# netx90_app register map
File version: 1.0
CPU: CM4 r0p1, little endian, MPU, FPU, 4 interrupt priority bits, 78 interrupts
Registers are 32-bit, read-write, reset 0x0 unless marked. A register's access mark holds for its fields unless they carry their own. Offsets are from the block's base; [hi:lo] are bit positions; {n}, {i} and the like mark numbered series; 'fields as' and 'values as' point back to an identical list.

## idpm_com
Base 0xFF001B00
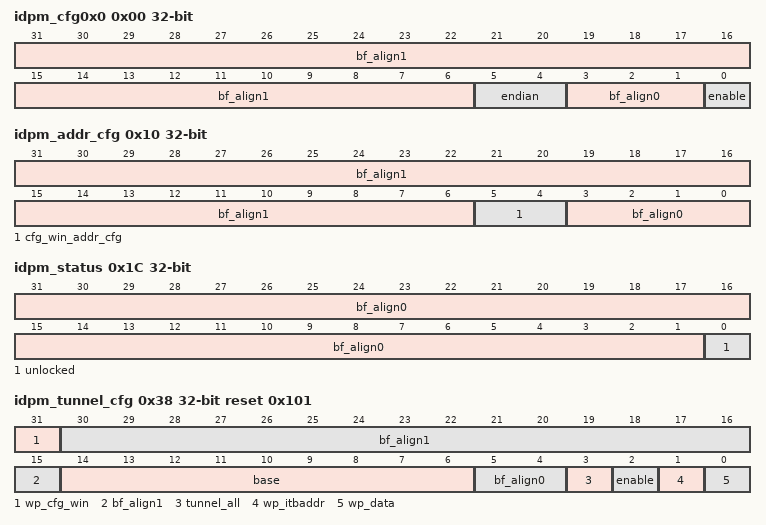
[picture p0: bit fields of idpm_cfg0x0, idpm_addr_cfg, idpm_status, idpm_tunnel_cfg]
0x00 idpm_cfg0x0 (reset mask 0x31) — DPM IO Control Register 0.
  [31:6] bf_align1 — bitField alignment value for aeabi compatibility
  [5:4] endian — Endianess of 32 bit (DWord) address alignment (B0: least significant byte, B3: most significant byte): { | | | | | coding Address A+3 A+2 A+1 A+0 00 little endian B3 B2 B1 B0 01 16 bit big endian B2 B3 B0 B1 10 32 bit big endian B0 B1 B2 B3 11 reserved } Little endian is used netX inside. If big endian host device is used, set to this 01 or 10 according to host device data width.
  [3:1] bf_align0 — bitField alignment value for aeabi compatibility
  [0] enable — Global IDPM enable bit. The IDPM module must be enabled by the INTLOGIC area before the host area (i.e. DPM mirrors of INTRAMHS) can be used. While disabled all host access (access to DPM mirrors of INTRAMHS) will be ignored. Read will return 0x0bad0bad.
0x10 idpm_addr_cfg (reset mask 0x30) — DPM External Address Configuration Register.
  [31:6] bf_align1 — bitField alignment value for aeabi compatibility
  [5:4] cfg_win_addr_cfg — Location of the DPM Configuration Window (Window 0). Supported settings are: 00: Low Configuration Window: The Configuration Window is located in the first 256 bytes of external DPM address range (0x0 to 0xff). It is located before the first enabled Data Window (1 to 4). 01: High Configuration Window: The Configuration Window is located in the last 256 bytes of external DPM address range. Example: 'addr_range' is 8kB: Configuration Window is located in 0x1F00..0x1FFF. 10: reserved. 11: Configuration Window is disabled for external DPM access. Full DPM address range can be used for Windows 1 to 4. Note: The Configuration Window 0 has higher priority than normal DPM Window. The location of the Configuration Window does not depend on the Data Window configuration (the setting of the 'dpm_winX_end' or 'dpm_winX_map' registers). I.e. for setting '00' (low Configuration Window) the first enabled Data Window starts at address 0x100. For setting '01' (high Configuration Window) it would hide the last 256 bytes of the last enabled Data Window when this is configured to end on the last external address. The Configuration Window 0 has lower priority than Access Tunnel. I.e. the Access Tunnel could be laid over the configuration window.
  [3:0] bf_align0 — bitField alignment value for aeabi compatibility
0x1C idpm_status ro (reset mask 0x1) — DPM Status Register.
  [31:1] bf_align0 — bitField alignment value for aeabi compatibility
  [0] unlocked — DPM is locked during netX power up and boot phase. DPM access to other addresses than DPM configuration window 0 cannot be done before this bit is set to 1. Write access to data windows (netX AHB area) will be ignored and read access will deliver invalid data while locked. Poll for 1 after power-up or reset.
0x38 idpm_tunnel_cfg reset 0x101 (reset mask 0x80007FCF) — description too long, please enter short description.
  [31] wp_cfg_win — Write-protect tunnel configuration inside the configuration window 0. 0: The two tunnel configuration registers ('idpm_tunnel_cfg' and 'idpm_itbaddr') can be programmed via configuration window 0 and the INTLOGIC_SYS-IDPM address area. 1: The tunnel configuration registers ('idpm_tunnel_cfg' and 'idpm_itbaddr') cannot be programmed by the host via configuration window 0 (they are read-only for the host there). They can only be programmed via the INTLOGIC_SYS-IDPM address area. Note: Set this bit to protect the NETX from reconfiguring the tunnel by the host when configuration window 0 is activated for the host (e.g. for IRQ handling).
  [30:15] bf_align1 — bitField alignment value for aeabi compatibility
  [14:6] base — DPM Access Tunnel (DATunnel) Base Address divided by 64 on external visible address space. Note: Default setting for tunnel base is starting on external address 0x100.
  [5:4] bf_align0 — bitField alignment value for aeabi compatibility
  [3] tunnel_all — Enable/disable the ITBAddr configuration register at tunnel offset 0x3C. 0: Only 15 DWords are tunneled to the internal tunnel target. The idpm_itbaddr is available at offset 0x3C. One DWord of the tunnel target area is hidden by idpm_itbaddr. 1: All 16 DWords are tunneled to the internal tunnel target. The idpm_itbaddr is not available at offset 0x3C. All 64 tunnel target bytes can be reached (no hidden register). Note: Target mapping (base and map) will not be affected by this bit. Using a 'map' value not equal 0 will always rotate the tunnel target addresses.
  [2] enable — Enable/disable Access Tunnel function.
  [1] wp_itbaddr — ITBAddr is write-protected from host. 0: The ITBAddr is mirrored to offset 0x3C of the tunnel and can also be programmed there. 1: ITBAddr (Internal netX 32 bit Tunnel Target Base Address) is read-only for tunnel offset 0x3C. It can only be changed via configuration window 0 idpm_itbaddr address or the INTLOGIC IDPM area.
  [0] wp_data — Access Tunnel function is write-protected for data access (DWords 0 to 14 (15 for 'tunnel_all') of DATunnel). 0: Write access is forwarded through the tunnel. 1: Write access to DWords 0 to 14 (15 for 'tunnel_all') of DATunnel will be ignored. Data write protection for host is enabled by default and can be disabled by clearing this bit.
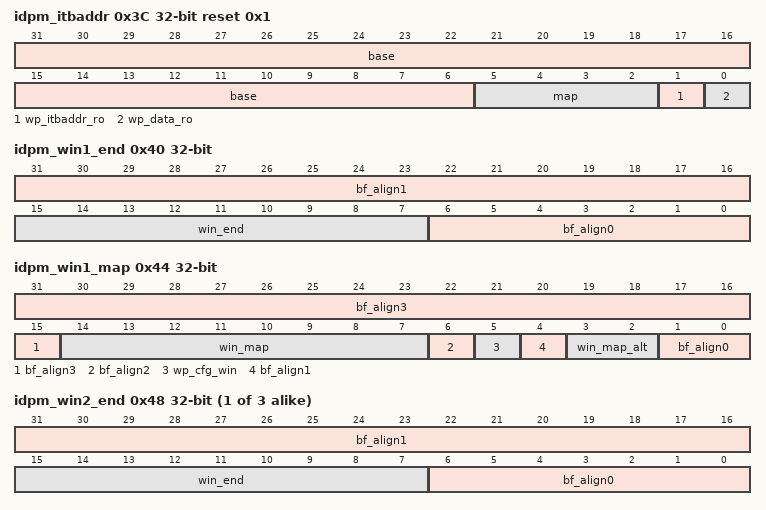
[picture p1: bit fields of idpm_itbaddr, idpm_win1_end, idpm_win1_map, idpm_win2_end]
0x3C idpm_itbaddr reset 0x1 — DPM Access Tunnel (DATunnel) netX Internal Target Base Address (ITBAddr) Configuration Register. For DPM Access Tunnel (DATunnel) function view description of dpm_tunnel_cfg register. This register contains ITBAddr value that can also be changed by host on last offset 0x3c (last DWord) of external DATunnel area (defined by bit field 'base' in 'dpm_tunnel_cfg' register). However this register can also be write-protected from host if bit 'wp_itbaddr' in 'dpm_tunnel_cfg' register is set. Write protection bits of DATunnel configured in 'dpm_tunnel_cfg' register can also be read from this register. Host can read access rights from these bits on last DWord of external DATunnel address area. Note: This register can be write-protected by the 'wp_cfg_win' and the 'wp_itbaddr'-bit of the 'idpm_tunnel_cfg' register.
  [31:6] base — Internal netX Tunnel Target Base Address (ITBAddr) divided by 64. View description of dpm_tunnel_cfg register.
  [5:2] map — Mapping part of ITBAddr. View description of dpm_tunnel_cfg register.
  [1] wp_itbaddr_ro — ITBAddr is write-protected from host. This is a read-only bit here. Its setting can be changed in 'dpm_tunnel_cfg' register. View description of dpm_tunnel_cfg register.
  [0] wp_data_ro — Access Tunnel function is write-protected from data access (DWords 0 to 14 of DATunnel). This is a read-only bit here. Its setting can be changed in 'dpm_tunnel_cfg' register. View description of dpm_tunnel_cfg register.
0x40 idpm_win1_end (reset mask 0xFF80) — DPM Window 1 End Address Configuration Register. Smallest DPM window configuration unit is 128 bytes (i.e. lowest 7 bits of address configuration are always 0). At address 0x0 DPM configuration window is mapped after reset (length: 256 bytes, containing all DPM addresses defined here). Each window starts at window end address of the preceding window. Hence external window 1 start address is 0x100, window 2 starts at value programmed in this register and so on. Note: This register can be write-protected by the 'wp_cfg_win'-bit of the 'idpm_win1_map' register. Note: Configuration Window 0 access detection has higher priority than normal DPM Window detection but lower priority than Access Tunnel access detection.
  [31:16] bf_align1 — bitField alignment value for aeabi compatibility
  [15:7] win_end — Window 1 End Address divided by 128. Last external address is win_end*128-1. Setting win_end to 0 will disable this window.
  [6:0] bf_align0 — bitField alignment value for aeabi compatibility
0x44 idpm_win1_map (reset mask 0x7FAC) — DPM Window 1 Address Map Configuration Register. Smallest DPM window configuration unit is 128 bytes (i.e. lowest 7 bits of address configuration are always 0). For further information view description of 'dpm_win1_end' register.
  [31:15] bf_align3 — bitField alignment value for aeabi compatibility
  [14:7] win_map — Window 1 Address Mapping. Internal access address HADDR to netX logic is combined by DPM interface by: HADDR[31:16]: unchanged, as it comes form accessing master HADDR[15:0]: mapped DPM address. This part of address is defined by programmed win_map value for each window. The value to be programmed is address bits 15 to 0 of netX internal window start address minus start address of the external window (i.e. end address of preceding window) . Example: Window n starts at 0x400 of external DPM address range (i.e. programmed win_end value of window (n-1) and targets netX address 0x05218000. For address calculation only lower 16 bits of netX address are relevant, i.e. 0x8000. The complete 16 bit address map value is then:0x8000-0x400=0x7C00. Hence the programmed 9 bit value must be 0x7C00>>7=0xf8.
  [6] bf_align2 — bitField alignment value for aeabi compatibility
  [5] wp_cfg_win — Write-protect window configuration inside the configuration window 0. 0: All 8 window configuration registers ('dpm_winX_and' and 'dpm_winX_map') can be programmed via configuration window 0 and the INTLOGIC-DPM address area. 1: All 8 window configuration registers ('dpm_winX_and' and 'dpm_winX_map') cannot be programmed by the host via configuration window 0 (they are read-only for the host there). They can only be programmed via the INTLOGIC-DPM address area. Note: Set this bit to protect the NETX from reconfiguring the window mapping by the host when configuration window 0 is activated for the host (e.g. for IRQ handling). Note: To protect the netX completely from host-access to not permitted address areas it must be ensured that also the remapping of the DPM tunne cannot be changed by the host (refer to register 'dpm_tunnel_cfg'). Note: This bit does only exist in the 'dpm_win1_map'-register but not in the registers for the higher windows. However this bit protect all DPM 'dpm_winX_and' and 'dpm_winX_map'-registers from being written via configuration window 0. Note: The 'wp_cfg_win'-bit is a new feature since netX4000 and netX6.
  [4] bf_align1 — bitField alignment value for aeabi compatibility
  [3:2] win_map_alt — Window 1 Alternative Address Mapping Configuration. Alternative Address Mapping can be generated by Triple Buffer Managers inside HANDSHAKE_CTRL unit. Coding: 00 : Alternative Address Mapping disabled. 01 : Alternative Address Mapping enabled: Use Triple Buffer Manager 0 from HANDSHAKE_CTRL unit. 10 : Alternative Address Mapping enabled: Use Triple Buffer Manager 1 from HANDSHAKE_CTRL unit. 11 : reserved If Alternative Address Mapping is enabled, mapping value is taken according to buffer status of related HANDSHAKE_CTRL Triple Buffer Manager as follows. { | buffer status used mapping value 00 (buffer 0) win_map entry of this register 01 (buffer 1) Alternative win_map value 1 of related HANDSHAKE_CTRL Triple Buffer Manager. 10 (buffer 2) Alternative win_map value 2 of related HANDSHAKE_CTRL Triple Buffer Manager. 11 (invalid buffer) win_map entry of this register } Note: Alternative Triple Buffer Manager win_map values can be programmed in HANDSHAKE_CTRL address area. Note: For netX4000 there are 2 IDPM and 2 HANDSHAKE_CTRL units. IDPM0 is always associated with HANDSHAKE_CTRL0 while IDPM1 is always associated with HANDSHAKE_CTRL1.
  [1:0] bf_align0 — bitField alignment value for aeabi compatibility
{0x38+8i} idpm_win{i}_end (reset mask 0xFF80) (i=2..4) — DPM Window {i} End Address Configuration Register. For detailed information refer to 'idpm_win1_end' register description. Note: This register can be write-protected by the 'wp_cfg_win'-bit of the 'idpm_win1_map' register.
  [31:16] bf_align1 — bitField alignment value for aeabi compatibility
  [15:7] win_end — Window {i} End Address divided by 128. Last external address is win_end*128-1.
  [6:0] bf_align0 — bitField alignment value for aeabi compatibility
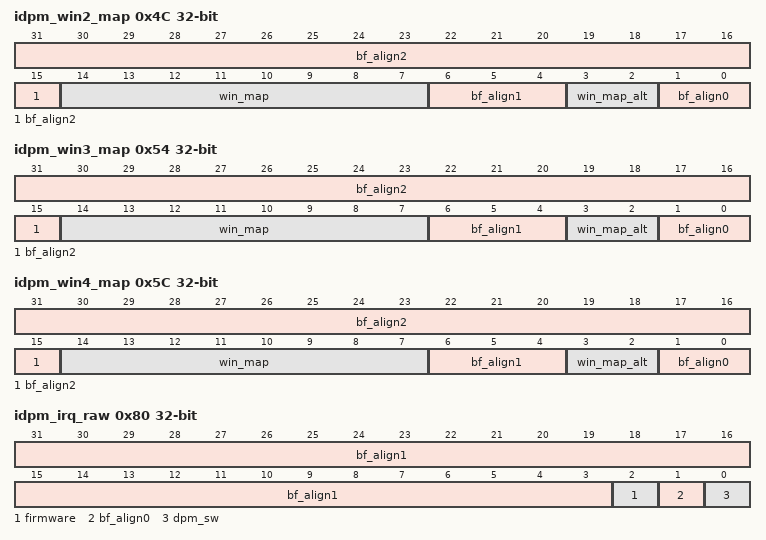
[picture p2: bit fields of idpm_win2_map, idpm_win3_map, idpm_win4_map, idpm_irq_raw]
0x4C idpm_win2_map (reset mask 0x7F8C) — DPM Window 2 Address Map Configuration Register. For detailed information refer to 'dpm_win1_map' register description. Note: This register can be write-protected by the 'wp_cfg_win'-bit of the 'idpm_win1_map' register.
  [31:15] bf_align2 — bitField alignment value for aeabi compatibility
  [14:7] win_map — Window address mapping.
  [6:4] bf_align1 — bitField alignment value for aeabi compatibility
  [3:2] win_map_alt — Window Alternative Address Mapping Configuration.
  [1:0] bf_align0 — bitField alignment value for aeabi compatibility
0x54 idpm_win3_map (reset mask 0x7F8C) — DPM Window 3 Address Map Configuration Register. For detailed information refer to 'dpm_win1_map' register description. Note: This register can be write-protected by the 'wp_cfg_win'-bit of the 'idpm_win1_map' register.
  [31:15] bf_align2 — bitField alignment value for aeabi compatibility
  [14:7] win_map — Window map address.
  [6:4] bf_align1 — bitField alignment value for aeabi compatibility
  [3:2] win_map_alt — Window Alternative Address Mapping Configuration.
  [1:0] bf_align0 — bitField alignment value for aeabi compatibility
0x5C idpm_win4_map (reset mask 0x7F8C) — DPM Window 4 Address Map Configuration Register. For detailed information refer to 'dpm_win1_map' register description. Note: This register can be write-protected by the 'wp_cfg_win'-bit of the 'idpm_win1_map' register.
  fields as idpm_win3_map
0x80 idpm_irq_raw ro (reset mask 0x5) — DPM Raw (before masking) IRQ Status Register. If a bit is set, the related interrupt is asserted. Interrupts must be reset in interrupt generating module. Interrupts cannot be cleared here. Important: There are two completely independent sets of IRQ registers: IRQ register-set 1: 'dpm_irq_raw' (and related registers e.g. 'dpm_irq_irq_*' registers). IRQ register-set 2: 'dpm_firmware_irq_* registers' (netx50 compatible register set: DPM_HOST_INT_EN0,2 DPM_HOST_INT_STA0,2). Programming (masking or clearing IRQs) of one register-set has no impact to the other register-set even if some IRQs can be found in both sets (e.g. com0). Note: The 'dpm_sw' IRQ can be controlled by the 'dpm_sw_irq' register. for each IRQ target. The 'dpm_sw' will be set inside the 'dpm_irq_raw' register when the 'dpm_sw' is activated for at least one IRQ target. But each IRQ target obtains only the 'dpm_sw' IRQ state programmed for this target inside the 'dpm_sw_irq' register. For an example view description of 'dpm_sw_irq' register. Note: The 'firmware' IRQ can be used to flag handshake and netX firmware system status events to the host. Firmware IRQ generation can be controlled by dpm_firmware_irq_mask register. Detailed firmware IRQ status can be read from dpm_firmware_irq_raw register.
  [31:3] bf_align1 — bitField alignment value for aeabi compatibility
  [2] firmware — raw combined handshake-cell and SYS_STA firmware interrupt
  [1] bf_align0 — bitField alignment value for aeabi compatibility
  [0] dpm_sw — raw software IRQ for IRQ targets interrupt
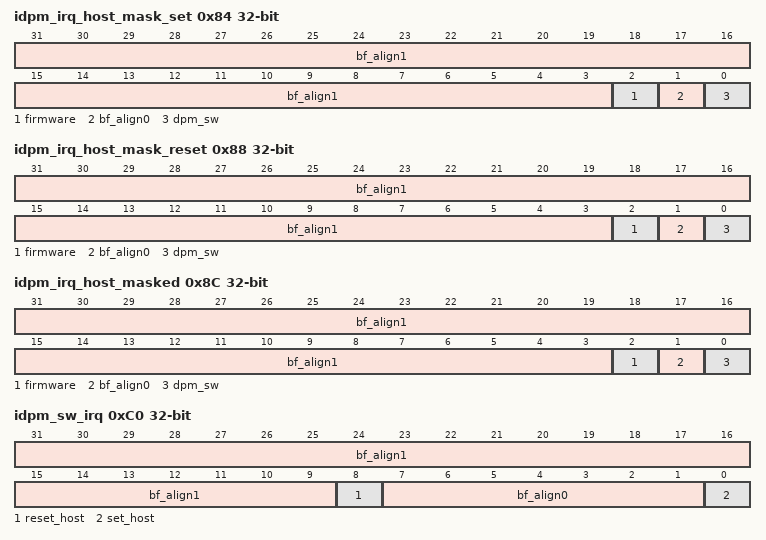
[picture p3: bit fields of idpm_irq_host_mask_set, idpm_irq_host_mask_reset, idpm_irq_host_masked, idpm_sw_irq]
0x84 idpm_irq_host_mask_set (reset mask 0x5) — DPM Interrupt Mask Register for IDPM host interrupt. Write access with '1' sets related interrupt mask bits (enables interrupt request for corresponding interrupt source). Write access with '0' does not influence related interrupt mask bit. Read access shows actual interrupt mask. If a mask bit is set, the related interrupt will activate the IRQ for IDPM host interrupt. Interrupts must be reset in interrupt generating module. Interrupts cannot be cleared here. To release IRQ for IDPM host interrupt without clearing interrupt in module, reset related mask bit to 0. Note: For further information view description of 'dpm_irq_raw' register.
  [31:3] bf_align1 — bitField alignment value for aeabi compatibility
  [2] firmware — set combined handshake-cell and SYS_STA firmware interrupt mask for IDPM host interrupt
  [1] bf_align0 — bitField alignment value for aeabi compatibility
  [0] dpm_sw — set software IRQ for IRQ targets interrupt mask for IDPM host interrupt
0x88 idpm_irq_host_mask_reset (reset mask 0x5) — DPM Interrupt Mask Reset Register for IDPM host interrupt. Write access with '1' resets related interrupt mask bits (disables interrupt request for corresponding interrupt source). Write access with '0' does not influence related interrupt mask bit. Read access shows actual interrupt mask. If a mask bit is set, the related interrupt will activate the IRQ for IDPM host interrupt. Interrupts must be reset in interrupt generating module. Interrupts cannot be cleared here. To release IRQ for IDPM host interrupt without clearing interrupt in module, reset related mask bit to 0. Note: For further information view description of 'dpm_irq_raw' register.
  [31:3] bf_align1 — bitField alignment value for aeabi compatibility
  [2] firmware — reset combined handshake-cell and SYS_STA firmware interrupt mask for IDPM host interrupt
  [1] bf_align0 — bitField alignment value for aeabi compatibility
  [0] dpm_sw — reset software IRQ for IRQ targets interrupt mask for IDPM host interrupt
0x8C idpm_irq_host_masked ro (reset mask 0x5) — DPM Masked Interrupt Status Register for IDPM host interrupt. A bit is set, when the related mask bit is set in 'dpm_irq_host_mask'-register and the related interrupt is asserted. IRQ for IDPM host interrupt is asserted if at least one bit is set here. Interrupts must be reset in interrupt generating module. Interrupts cannot be cleared here. To release IRQ for IDPM host interrupt without clearing interrupt in module, reset related mask bit to 0. Note: For further information view description of 'dpm_irq_raw' register.
  [31:3] bf_align1 — bitField alignment value for aeabi compatibility
  [2] firmware — masked combined handshake-cell and SYS_STA firmware interrupt state for IDPM host interrupt
  [1] bf_align0 — bitField alignment value for aeabi compatibility
  [0] dpm_sw — masked software IRQ for IRQ targets interrupt state for IDPM host interrupt
0xC0 idpm_sw_irq (reset mask 0x101) — DPM Register for Software Interrupt Generation to Host and netX Interrupt Targets. Host and netX masters can generate an interrupt to netX interrupt targets (e.g. ARM-VIC) by this register. To propagate interrupt states from this register to the interrupt target the 'idpm_sw' IRQ must be enabled inside the appropriate interrupt controller (e.g. the ARM-VIC). Note: There is a set and a reset bit for the sw-IRQ to avoid read-modify-write sequences. When both (set and reset) bits are set at the same time, the interrupt will be set (set will win). The reset-bit is always 0 for read. The set-bit shows the current interrupt status when read. Note: This register is a new netx51/52 feature..
  [31:9] bf_align1 — bitField alignment value for aeabi compatibility
  [8] reset_host — Reset 'dpm_sw' IRQ for host (always 0 when read)
  [7:1] bf_align0 — bitField alignment value for aeabi compatibility
  [0] set_host — Set 'dpm_sw' IRQ for host (current 'dpm_sw' status for host when read)
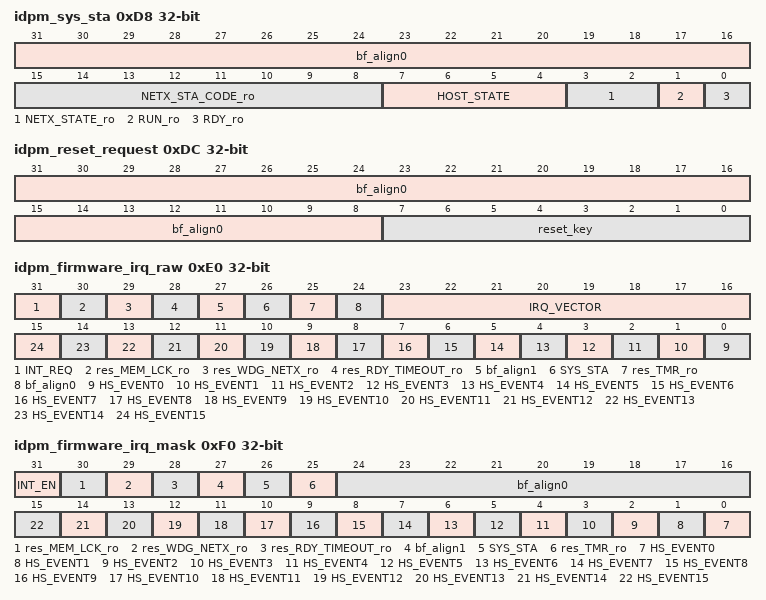
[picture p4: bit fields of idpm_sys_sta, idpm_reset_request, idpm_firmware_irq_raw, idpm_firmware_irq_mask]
0xD8 idpm_sys_sta (reset mask 0xFFFF) — DPM System Status Information Register. This register can be used for firmware status information. Note: This register is NOT fully compatible to netx50 DPM_HOST_SYS_STAT register: Only the HOST_STATE-bits of DPM0 can be read from the 'netx_status'-register inside ASIC_CTRL address area. The HOST_STATE-bits of DPM1 and IDPM can not be read from the 'netx_status'-register inside ASIC_CTRL address area.
  [31:16] bf_align0 — bitField alignment value for aeabi compatibility
  [15:8] NETX_STA_CODE_ro — Bit field for Hilscher firmware compatibility (read only). Note: This bit field can be changed by 'netx_status'-register inside ASIC_CTRL address area.
  [7:4] HOST_STATE — Bit field for Hilscher firmware. Note: This bit field can NOT be read from 'netx_status'-register inside ASIC_CTRL address area.
  [3:2] NETX_STATE_ro — Bit field for Hilscher firmware compatibility. Note: This bit field can be changed by 'netx_status'-register inside ASIC_CTRL address area.
  [1] RUN_ro — Output state of netX RUN LED IO. Note: This bit field can be changed by 'rdy_run_cfg'-register inside ASIC_CTRL address area.
  [0] RDY_ro — Output state of netX RDY LED IO. Note: This bit field can be changed by 'rdy_run_cfg'-register inside ASIC_CTRL address area.
0xDC idpm_reset_request (reset mask 0xFF) — DPM Reset Request Register. Note: This register is compatible to netx50 DPM_HOST_RESET_REQ register
  [31:8] bf_align0 — bitField alignment value for aeabi compatibility
  [7:0] reset_key — Reset key sequence register. A netx hardware reset is generated if the following sequence is written to this register: 1st access: write 0x00 2nd access: write 0x01 3rd access: write 0x03 4th access: write 0x07 5th access: write 0x0f 6th access: write 0x1f 7th access: write 0x3f 8th access: write 0x7f To issue a reset the sequence must not be interrupted by a write access to another register of this DPM module register area. Writing 0x00 will always restart the sequence. Reading this register will always provide the next write data. Hence it is also possible performing 8 times a read-write sequence to this register (however this is not required, simply writing the sequence will also succeed). Writing any other value than the next expected by the DPM module, the internal reset FSM will be cleared and the register will return 0x00 for the next read. The FSM will also be cleared if the sequence is interrupted by a write access to any other register of this DPM register area. The sequence must be restarted with the 1st access (writing 0x00) in this case. Note: The DPM reset request is internally a level-signal, not only a pulse. Additionally the DPM reset request could be masked (disabled) by the global reset controller (netX4000). If the DPM reset request is disabled globally but issued by the DPM module there are two possibilities to get out of this: 1.: Enable the DPM reset in the global reset controller. The NETX will be reset then immediately (typically this must be done by the NETX-side CPU and cannot be done by a host). 2.: Write 0x00 (or any other value except 0xFF) to this register or perform a write access to any other register of this DPM register area. This will clear the DPM reset FSM and the reset request of this DPM module to the global reset controller.
0xE0 idpm_firmware_irq_raw (reset mask 0xF6FFFFFF) — 1st netx50 compatible DPM Interrupt Status Register (related to 'dpm_firmware_irq_mask'-register). Writing a '1' to an IRQ flag will clear the Interrupt. This is always done even if related bit inside 'dpm_firmware_irq_mask'-register is not set (this is compatible to netx50). Important: There are two completely independent sets of IRQ registers: IRQ register-set 1: 'dpm_irq_raw' (and related registers e.g. 'dpm_irq_irq_*' registers). IRQ register-set 2: 'dpm_firmware_irq_* registers' (netx50 compatible register set: DPM_HOST_INT_EN0,2 DPM_HOST_INT_STA0,2). Programming (masking or clearing IRQs) of one register-set has no impact to the other register-set even if some IRQs can be found in both sets (e.g. com0). Note: This register is compatible to netx50 DPM_HOST_INT_STAT0 register, however some unused IRQs have been removed. Note: For netX4000 there are 2 IDPM and 2 HANDSHAKE_CTRL units. IDPM0 is always associated with HANDSHAKE_CTRL0 while IDPM1 is always associated with HANDSHAKE_CTRL1. Note: The 2nd firmware IRQ register set (dpm_firmware_irq_mask2, DPM_HOST_INT_EN2, dpm_firmware_irq_raw2, DPM_HOST_INT_STAT2) are obsolete since netx4000. Some functions moved to the main DPM IRQ register set (view dpm_irq_raw).
  [31] INT_REQ — Interrupt Request for IRQs handled in this register. 0: No Interrupts to host requested by IRQ sources handled in this register. 1: IRQ sources handled in this register request a host IRQ. Note: This bit is masked by INT_EN-bit in dpm_firmware_irq_mask register. For propagation of INT_REQ to host, ARM or xPIC, INT_EN-bit must be set and firmware IRQ must be activated in related dpm_irq_* register.
  [30] res_MEM_LCK_ro — reserved for Memory Lock IRQ flag (not available in this netX version).
  [29] res_WDG_NETX_ro — reserved for netX supervision Watchdog Timeout IRQ flag (not available in this netX version).
  [28] res_RDY_TIMEOUT_ro — reserved, DPM_RDY timeout error does not exist for IDPM.
  [27] bf_align1 — bitField alignment value for aeabi compatibility
  [26] SYS_STA — System Status Change IRQ flag.
  [25] res_TMR_ro — reserved for Timer IRQ flag (not available in this netX version).
  [24] bf_align0 — bitField alignment value for aeabi compatibility
  [23:16] IRQ_VECTOR — Interrupt Vector according to status flags generated by enabled IRQ sources. { | Code IRQ status 0x00 No IRQ. ---- ------- 0x10 Handshake Cell 0 IRQ. 0x11 Handshake Cell 1 IRQ. 0x12 Handshake Cell 2 IRQ. 0x13 Handshake Cell 3 IRQ. 0x14 Handshake Cell 4 IRQ. 0x15 Handshake Cell 5 IRQ. 0x16 Handshake Cell 6 IRQ. 0x17 Handshake Cell 7 IRQ. 0x18 Handshake Cell 8 IRQ. 0x19 Handshake Cell 9 IRQ. 0x1a Handshake Cell 10 IRQ. 0x1b Handshake Cell 11 IRQ. 0x1c Handshake Cell 12 IRQ. 0x1d Handshake Cell 13 IRQ. 0x1e Handshake Cell 14 IRQ. 0x1f Handshake Cell 15 IRQ. ---- ------- 0x70 SYS_STA IRQ Other values are reserved.} Note: The current IRQ state in VECTOR depends only on the single IRQ enable bits. It does not depend on global IRQ enable INT_EN. VECTOR shows always the highest priority enabled flagged IRQ even is INT_EN is '0'.
  [n] HS_EVENT{n} (n=0..15) — Handshake Event {n} IRQ status flag.
0xF0 idpm_firmware_irq_mask (reset mask 0xF600FFFF) — DPM Handshake Interrupt Enable Register. Only netx50 compatible 'dpm_firmware_irq' registers are related to settings of this register. Note: This register is compatible to netx50 DPM_HOST_INT_EN0 register, however some unused IRQs have been removed. Note: HS_EVENT-bits are not read-only. This is netX50 compliant. Recent netX50 Documentation marks HS_EVENT-bits as read-only. This is an dokumentation error. For netX50 compatibility, these bits can also be controlled from netX-side in HANDSHAKE_CTRL address area. Note: The 2nd firmware IRQ register set (dpm_firmware_irq_mask2, DPM_HOST_INT_EN2, dpm_firmware_irq_raw2, DPM_HOST_INT_STAT2) are obsolete since netx4000. Some functions moved to the main DPM IRQ register set (view dpm_irq_raw).
  [31] INT_EN — Interrupt Enable for IRQs handled in this register. Only if this bit is set, global firmware IRQ will be asserted to host CPU, ARM or xPIC by dpm_irq_* registers. 0: No Interrupts to host, ARM or xPIC are generated by IRQ sources handled in this register. 1: Enabled IRQ sources handled in this register generate a host, ARM or xPIC IRQ if asserted. Note: Enable bits for single IRQ events are not affected if this bit is set or reset.
  [30] res_MEM_LCK_ro — reserved for Memory Lock IRQ (not available in this netX version).
  [29] res_WDG_NETX_ro — reserved for netX supervision Watchdog Timeout IRQ (not available in this netX version).
  [28] res_RDY_TIMEOUT_ro — reserved, DPM_RDY timeout error does not exist for IDPM.
  [27] bf_align1 — bitField alignment value for aeabi compatibility
  [26] SYS_STA — System Status Change IRQ Enable.
  [25] res_TMR_ro — reserved for Timer IRQ (not available in this netX version).
  [24:16] bf_align0 — bitField alignment value for aeabi compatibility
  [n] HS_EVENT{n} (n=0..15) — Handshake Event {n} IRQ Enable (also netX-controllable by HANDSHAKE_CTRL, netX50 comp.).
0xFC idpm_netx_version ro — DPM netX Version Register. This register is mirrored form asic_ctrl register area and can be set during netX booting phase by netX firmware. This register is not valid if unlocked bit is not set in dpm_status register.
  [31:0] netx_version — netX version from version register.
